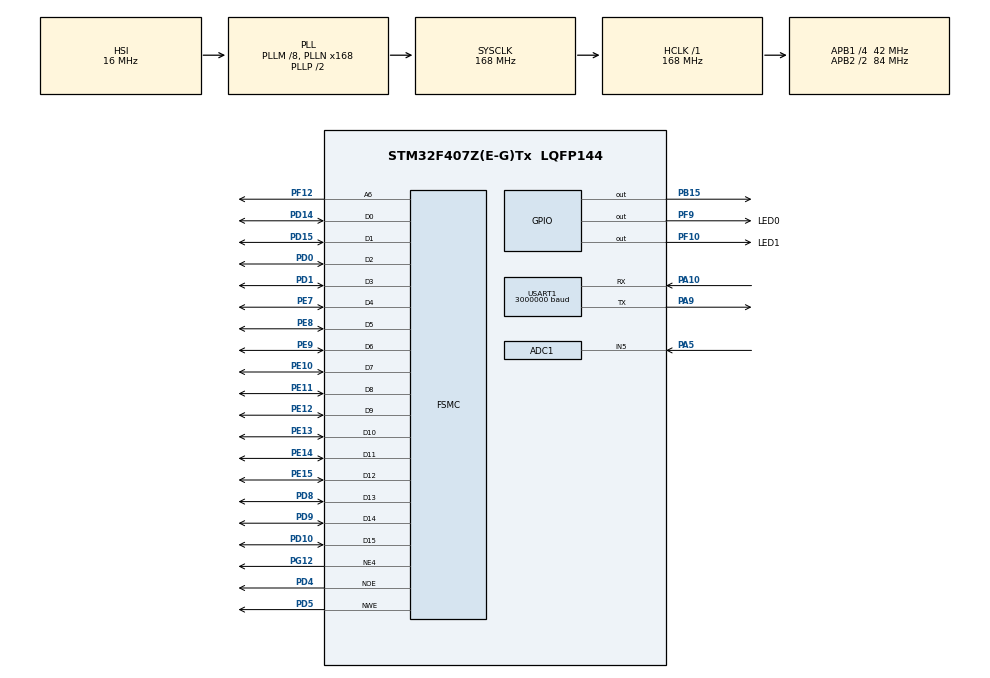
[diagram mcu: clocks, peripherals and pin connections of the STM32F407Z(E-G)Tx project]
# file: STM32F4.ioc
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ADC1.Channel-0\#ChannelRegularConversion=ADC_CHANNEL_5
ADC1.ContinuousConvMode=ENABLE
ADC1.DMAContinuousRequests=ENABLE
ADC1.NbrOfConversionFlag=1
ADC1.Rank-0\#ChannelRegularConversion=1
ADC1.SamplingTime-0\#ChannelRegularConversion=ADC_SAMPLETIME_3CYCLES
ADC1.ScanConvMode=DISABLE
ADC1.master=1
Dma.ADC1.2.Direction=DMA_PERIPH_TO_MEMORY
Dma.ADC1.2.FIFOMode=DMA_FIFOMODE_DISABLE
Dma.ADC1.2.Instance=DMA2_Stream0
Dma.ADC1.2.MemDataAlignment=DMA_MDATAALIGN_WORD
Dma.ADC1.2.MemInc=DMA_MINC_ENABLE
Dma.ADC1.2.Mode=DMA_CIRCULAR
Dma.ADC1.2.PeriphDataAlignment=DMA_PDATAALIGN_WORD
Dma.ADC1.2.PeriphInc=DMA_PINC_DISABLE
Dma.ADC1.2.Priority=DMA_PRIORITY_VERY_HIGH
Dma.Request0=USART1_RX
Dma.Request1=USART1_TX
Dma.Request2=ADC1
Dma.USART1_RX.0.Direction=DMA_PERIPH_TO_MEMORY
Dma.USART1_RX.0.FIFOMode=DMA_FIFOMODE_DISABLE
Dma.USART1_RX.0.Instance=DMA2_Stream2
Dma.USART1_RX.0.MemDataAlignment=DMA_MDATAALIGN_BYTE
Dma.USART1_RX.0.MemInc=DMA_MINC_ENABLE
Dma.USART1_RX.0.Mode=DMA_NORMAL
Dma.USART1_RX.0.PeriphDataAlignment=DMA_PDATAALIGN_BYTE
Dma.USART1_RX.0.PeriphInc=DMA_PINC_DISABLE
Dma.USART1_RX.0.Priority=DMA_PRIORITY_LOW
Dma.USART1_TX.1.Direction=DMA_MEMORY_TO_PERIPH
Dma.USART1_TX.1.FIFOMode=DMA_FIFOMODE_DISABLE
Dma.USART1_TX.1.Instance=DMA2_Stream7
Dma.USART1_TX.1.MemDataAlignment=DMA_MDATAALIGN_BYTE
Dma.USART1_TX.1.MemInc=DMA_MINC_ENABLE
Dma.USART1_TX.1.Mode=DMA_NORMAL
Dma.USART1_TX.1.PeriphDataAlignment=DMA_PDATAALIGN_BYTE
Dma.USART1_TX.1.PeriphInc=DMA_PINC_DISABLE
Dma.USART1_TX.1.Priority=DMA_PRIORITY_LOW
FSMC.BusTurnAroundDuration1=0
FSMC.DataSetupTime1=60
FSMC.ExtendedAddressSetupTime1=9
FSMC.ExtendedBusTurnAroundDuration1=0
FSMC.ExtendedDataSetupTime1=8
FSMC.ExtendedMode1=FSMC_EXTENDED_MODE_ENABLE
Mcu.Family=STM32F4
Mcu.Name=STM32F407Z(E-G)Tx
Mcu.Package=LQFP144
NVIC.DMA2_Stream0_IRQn=true\:0\:0\:false\:false\:true\:false\:true\:true
NVIC.DMA2_Stream2_IRQn=true\:0\:0\:false\:false\:true\:false\:true\:true
NVIC.DMA2_Stream7_IRQn=true\:0\:0\:false\:false\:true\:false\:true\:true
NVIC.PriorityGroup=NVIC_PRIORITYGROUP_4
NVIC.TIM1_UP_TIM10_IRQn=true\:0\:0\:false\:false\:true\:true\:true\:true
NVIC.USART1_IRQn=true\:0\:0\:false\:false\:true\:true\:true\:true
PA10.Mode=Asynchronous
PA10.Signal=USART1_RX
PA13.Mode=Serial_Wire
PA13.Signal=SYS_JTMS-SWDIO
PA14.Mode=Serial_Wire
PA14.Signal=SYS_JTCK-SWCLK
PA5.Signal=ADCx_IN5
PA9.Mode=Asynchronous
PA9.Signal=USART1_TX
PB15.GPIO_PuPd=GPIO_PULLUP
PB15.GPIO_Speed=GPIO_SPEED_FREQ_MEDIUM
PB15.Signal=GPIO_Output
PD0.GPIO_PuPd=GPIO_PULLUP
PD0.Signal=FSMC_D2_DA2
PD1.GPIO_PuPd=GPIO_PULLUP
PD1.Signal=FSMC_D3_DA3
PD10.GPIO_PuPd=GPIO_PULLUP
PD10.Signal=FSMC_D15_DA15
PD14.GPIO_PuPd=GPIO_PULLUP
PD14.Signal=FSMC_D0_DA0
PD15.GPIO_PuPd=GPIO_PULLUP
PD15.Signal=FSMC_D1_DA1
PD4.GPIO_PuPd=GPIO_PULLUP
PD4.Signal=FSMC_NOE
PD5.GPIO_PuPd=GPIO_PULLUP
PD5.Signal=FSMC_NWE
PD8.GPIO_PuPd=GPIO_PULLUP
PD8.Signal=FSMC_D13_DA13
PD9.GPIO_PuPd=GPIO_PULLUP
PD9.Signal=FSMC_D14_DA14
PE10.GPIO_PuPd=GPIO_PULLUP
PE10.Signal=FSMC_D7_DA7
PE11.GPIO_PuPd=GPIO_PULLUP
PE11.Signal=FSMC_D8_DA8
PE12.GPIO_PuPd=GPIO_PULLUP
PE12.Signal=FSMC_D9_DA9
PE13.GPIO_PuPd=GPIO_PULLUP
PE13.Signal=FSMC_D10_DA10
PE14.GPIO_PuPd=GPIO_PULLUP
PE14.Signal=FSMC_D11_DA11
PE15.GPIO_PuPd=GPIO_PULLUP
PE15.Signal=FSMC_D12_DA12
PE7.GPIO_PuPd=GPIO_PULLUP
PE7.Signal=FSMC_D4_DA4
PE8.GPIO_PuPd=GPIO_PULLUP
PE8.Signal=FSMC_D5_DA5
PE9.GPIO_PuPd=GPIO_PULLUP
PE9.Signal=FSMC_D6_DA6
PF10.GPIO_Label=LED1
PF10.GPIO_PuPd=GPIO_PULLUP
PF10.PinState=GPIO_PIN_SET
PF10.Signal=GPIO_Output
PF12.GPIO_PuPd=GPIO_PULLUP
PF12.Signal=FSMC_A6
PF9.GPIO_Label=LED0
PF9.GPIO_ModeDefaultOutputPP=GPIO_MODE_OUTPUT_PP
PF9.GPIO_PuPd=GPIO_PULLUP
PF9.PinState=GPIO_PIN_SET
PF9.Signal=GPIO_Output
PG12.GPIO_PuPd=GPIO_PULLUP
PG12.Mode=NorPsramChipSelect4_1
PG12.Signal=FSMC_NE4
PH0-OSC_IN.Mode=HSE-External-Oscillator
PH0-OSC_IN.Signal=RCC_OSC_IN
PH1-OSC_OUT.Mode=HSE-External-Oscillator
PH1-OSC_OUT.Signal=RCC_OSC_OUT
ProjectManager.HeapSize=0x200
ProjectManager.StackSize=0x400
ProjectManager.TargetToolchain=STM32CubeIDE
RCC.48MHZClocksFreq_Value=84000000
RCC.AHBFreq_Value=168000000
RCC.APB1CLKDivider=RCC_HCLK_DIV4
RCC.APB1Freq_Value=42000000
RCC.APB1TimFreq_Value=84000000
RCC.APB2CLKDivider=RCC_HCLK_DIV2
RCC.APB2Freq_Value=84000000
RCC.APB2TimFreq_Value=168000000
RCC.CortexFreq_Value=168000000
RCC.HCLKFreq_Value=168000000
RCC.HSE_VALUE=25000000
RCC.HSI_VALUE=16000000
RCC.LSE_VALUE=32768
RCC.PLLM=8
RCC.PLLN=168
RCC.SYSCLKFreq_VALUE=168000000
RCC.SYSCLKSource=RCC_SYSCLKSOURCE_PLLCLK
RCC.VCOOutputFreq_Value=336000000
SH.ADCx_IN5.0=ADC1_IN5,IN5
SH.FSMC_A6.0=FSMC_A6,A6_1
SH.FSMC_D0_DA0.0=FSMC_D0,16b-d1
SH.FSMC_D10_DA10.0=FSMC_D10,16b-d1
SH.FSMC_D11_DA11.0=FSMC_D11,16b-d1
SH.FSMC_D12_DA12.0=FSMC_D12,16b-d1
SH.FSMC_D13_DA13.0=FSMC_D13,16b-d1
SH.FSMC_D14_DA14.0=FSMC_D14,16b-d1
SH.FSMC_D15_DA15.0=FSMC_D15,16b-d1
SH.FSMC_D1_DA1.0=FSMC_D1,16b-d1
SH.FSMC_D2_DA2.0=FSMC_D2,16b-d1
SH.FSMC_D3_DA3.0=FSMC_D3,16b-d1
SH.FSMC_D4_DA4.0=FSMC_D4,16b-d1
SH.FSMC_D5_DA5.0=FSMC_D5,16b-d1
SH.FSMC_D6_DA6.0=FSMC_D6,16b-d1
SH.FSMC_D7_DA7.0=FSMC_D7,16b-d1
SH.FSMC_D8_DA8.0=FSMC_D8,16b-d1
SH.FSMC_D9_DA9.0=FSMC_D9,16b-d1
SH.FSMC_NOE.0=FSMC_NOE,Lcd1
SH.FSMC_NWE.0=FSMC_NWE,Lcd1
TIM1.AutoReloadPreload=TIM_AUTORELOAD_PRELOAD_ENABLE
TIM1.Period=10000-1
TIM1.Prescaler=168-1
TIM7.Period=1
TIM7.Prescaler=83
USART1.BaudRate=3000000
USART1.VirtualMode=VM_ASYNC
VP_TIM1_VS_ClockSourceINT.Mode=Internal
VP_TIM7_VS_ClockSourceINT.Mode=Enable_Timer
board=custom

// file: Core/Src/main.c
/* USER CODE BEGIN Header */
/**
  ******************************************************************************
  * @file           : main.c
  * @brief          : Main program body
  ******************************************************************************
  * @attention
  *
  * Copyright (c) 2022 STMicroelectronics.
  * All rights reserved.
  *
  * This software is licensed under terms that can be found in the LICENSE file
  * in the root directory of this software component.
  * If no LICENSE file comes with this software, it is provided AS-IS.
  *
  ******************************************************************************
  */
/* USER CODE END Header */
#include "main.h"
#include "adc.h"
#include "dma.h"
#include "tim.h"
#include "usart.h"
#include "gpio.h"
#include "fsmc.h"

/* USER CODE BEGIN Includes */
#include "common_inc.h"
#include "lcd.h"
#include "stdio.h"
/* USER CODE END Includes */

void SystemClock_Config(void);

/* USER CODE BEGIN 0 */
uint32_t ADC_Value[100];
uint8_t i;
float ad1 = 0;
/* USER CODE END 0 */

int main(void)
{

  /* MCU Configuration--------------------------------------------------------*/

  /* Reset of all peripherals, Initializes the Flash interface and the Systick. */
  HAL_Init();

  /* Configure the system clock */
  SystemClock_Config();

  /* Initialize all configured peripherals */
  MX_GPIO_Init();
  MX_DMA_Init();
  MX_TIM1_Init();
  MX_USART1_UART_Init();
  MX_FSMC_Init();
  MX_TIM7_Init();
  MX_ADC1_Init();
  /* USER CODE BEGIN 2 */
    LCD_Init();
    POINT_COLOR=RED;
    HAL_ADC_Start_DMA(&hadc1, ADC_Value, 100);
//    Main();
  /* USER CODE END 2 */

  /* Infinite loop */
  /* USER CODE BEGIN WHILE */
  while (1)
  {
      if(HAL_IS_BIT_SET(HAL_ADC_GetState(&hadc1), HAL_ADC_STATE_REG_EOC))
      {
          for(i = 0; i < 100; i++)
          {
              ad1 += ADC_Value[i];
//              LCD_ShowNum(30, 40,ADC_Value[i],4,24);
//              printf("Vol: %.4f \r\n", ADC_Value[i]*3.3f/4096);
          }
          ad1 /=  100.0;
//          printf("PA4 Reading Vol Value: %.4f \r\n", ad1*3.3f/4096);
          printf("%.4f \r\n", ad1*3.3f/4096);
//          HAL_Delay(500);

      }
//      LCD_ShowNum(30, 40,1234,4,24);
    /* USER CODE END WHILE */

  }
}

void SystemClock_Config(void)
{
  RCC_OscInitTypeDef RCC_OscInitStruct = {0};
  RCC_ClkInitTypeDef RCC_ClkInitStruct = {0};

  /** Configure the main internal regulator output voltage
  */
  __HAL_RCC_PWR_CLK_ENABLE();
  __HAL_PWR_VOLTAGESCALING_CONFIG(PWR_REGULATOR_VOLTAGE_SCALE1);

  /** Initializes the RCC Oscillators according to the specified parameters
  * in the RCC_OscInitTypeDef structure.
  */
  RCC_OscInitStruct.OscillatorType = RCC_OSCILLATORTYPE_HSI;
  RCC_OscInitStruct.HSIState = RCC_HSI_ON;
  RCC_OscInitStruct.HSICalibrationValue = RCC_HSICALIBRATION_DEFAULT;
  RCC_OscInitStruct.PLL.PLLState = RCC_PLL_ON;
  RCC_OscInitStruct.PLL.PLLSource = RCC_PLLSOURCE_HSI;
  RCC_OscInitStruct.PLL.PLLM = 8;
  RCC_OscInitStruct.PLL.PLLN = 168;
  RCC_OscInitStruct.PLL.PLLP = RCC_PLLP_DIV2;
  RCC_OscInitStruct.PLL.PLLQ = 4;
  if (HAL_RCC_OscConfig(&RCC_OscInitStruct) != HAL_OK)
  {
    Error_Handler();
  }

  /** Initializes the CPU, AHB and APB buses clocks
  */
  RCC_ClkInitStruct.ClockType = RCC_CLOCKTYPE_HCLK|RCC_CLOCKTYPE_SYSCLK
                              |RCC_CLOCKTYPE_PCLK1|RCC_CLOCKTYPE_PCLK2;
  RCC_ClkInitStruct.SYSCLKSource = RCC_SYSCLKSOURCE_PLLCLK;
  RCC_ClkInitStruct.AHBCLKDivider = RCC_SYSCLK_DIV1;
  RCC_ClkInitStruct.APB1CLKDivider = RCC_HCLK_DIV4;
  RCC_ClkInitStruct.APB2CLKDivider = RCC_HCLK_DIV2;

  if (HAL_RCC_ClockConfig(&RCC_ClkInitStruct, FLASH_LATENCY_5) != HAL_OK)
  {
    Error_Handler();
  }
}

void Error_Handler(void)
{
  __disable_irq();
  while (1)
  {
  }
}
